# MKM34Z7 register map
Vendor: Freescale Semiconductor, Inc.; Series: Kinetis_M; File version: 1.6
CPU: CM0PLUS r0p0, little endian, no MPU, no FPU, VTOR, 2 interrupt priority bits
Registers are 32-bit, read-write, reset 0x0 unless marked. A register's access mark holds for its fields unless they carry their own. Offsets are from the block's base; [hi:lo] are bit positions; {n}, {i} and the like mark numbered series.

## EWM — External Watchdog Monitor
Base 0x40061000; register names take the prefix EWM_
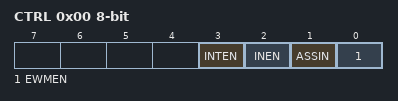
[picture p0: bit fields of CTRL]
0x00 CTRL 8-bit — Control Register
  [3] INTEN — Interrupt Enable.
  [2] INEN — Input Enable.
  [1] ASSIN — EWM_in's Assertion State Select.
  [0] EWMEN — EWM enable.
0x01 SERV 8-bit wo — Service Register
  [7:0] SERVICE — The EWM service mechanism requires the CPU to write two values to the SERV register: a first data byte of 0xB4, followed by a second data byte of 0x2C
0x02 CMPL 8-bit — Compare Low Register
  [7:0] COMPAREL — To prevent runaway code from changing this field, software should write to this field after a CPU reset even if the (default) minimum service time is required
0x03 CMPH 8-bit reset 0xFF — Compare High Register
  [7:0] COMPAREH — To prevent runaway code from changing this field, software should write to this field after a CPU reset even if the (default) maximum service time is required
0x04 CLKCTRL 8-bit — Clock Control Register
  [1:0] CLKSEL — EWM has 4 possible low power clock sources for running EWM counter
0x05 CLKPRESCALER 8-bit — Clock Prescaler Register
  [7:0] CLK_DIV — Selected low power source for running the EWM counter can be prescaled as below

## OSC — Oscillator
Base 0x40066000; register names take the prefix OSC_
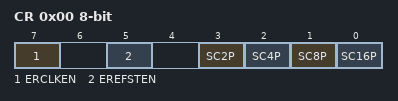
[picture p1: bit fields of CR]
0x00 CR 8-bit — OSC Control Register
  [7] ERCLKEN — External Reference Enable
    0=External reference clock is inactive; 1=External reference clock is enabled
  [5] EREFSTEN — External Reference Stop Enable
    0=External reference clock is disabled in Stop mode; 1=External reference clock stays enabled in Stop mode if ERCLKEN is set before entering Stop mode
  [3] SC2P — Oscillator 2 pF Capacitor Load Configure
    0=Disable the selection; 1=Add 2 pF capacitor to the oscillator load
  [2] SC4P — Oscillator 4 pF Capacitor Load Configure
    0=Disable the selection; 1=Add 4 pF capacitor to the oscillator load
  [1] SC8P — Oscillator 8 pF Capacitor Load Configure
    0=Disable the selection; 1=Add 8 pF capacitor to the oscillator load
  [0] SC16P — Oscillator 16 pF Capacitor Load Configure
    0=Disable the selection; 1=Add 16 pF capacitor to the oscillator load

## VREF — Voltage Reference
Base 0x4006F000; register names take the prefix VREF_
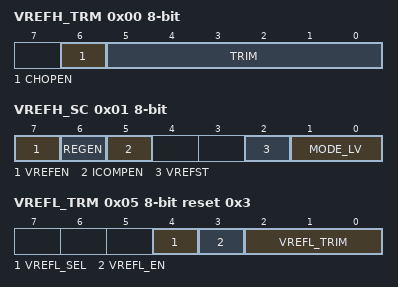
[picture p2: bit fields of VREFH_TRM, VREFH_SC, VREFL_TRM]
0x00 VREFH_TRM 8-bit — VREF Trim Register
  [6] CHOPEN — Chop oscillator enable. When set, internal chopping operation is enabled and the internal analog offset will be minimized.
    0=Chop oscillator is disabled; 1=Chop oscillator is enabled
  [5:0] TRIM — Trim bits
    0=Min; 63=Max
0x01 VREFH_SC 8-bit — VREF Status and Control Register
  [7] VREFEN — Internal Voltage Reference enable
    0=The module is disabled; 1=The module is enabled
  [6] REGEN — Regulator enable
    0=Internal 1.75 V regulator is disabled; 1=Internal 1.75 V regulator is enabled
  [5] ICOMPEN — Second order curvature compensation enable
    0=Disabled; 1=Enabled
  [2] VREFST ro — Internal Voltage Reference stable
    0=The module is disabled or not stable; 1=The module is stable
  [1:0] MODE_LV — Buffer Mode selection
    0=Bandgap on only, for stabilization and startup; 1=High power buffer mode enabled; 2=Low-power buffer mode enabled
0x05 VREFL_TRM 8-bit reset 0x3 — VREFL TRIM Register
  [4] VREFL_SEL — This bit selects between internal and external 1.2 V reference.
    0=Internal reference; 1=External reference
  [3] VREFL_EN — This bit enables the VREFL (0.4 V) reference buffer.
    0=Disable; 1=Enable
  [2:0] VREFL_TRIM — These bits trim the VREFL reference voltage in steps of 10 mV

## CMP0 — High-Speed Comparator (CMP), Voltage Reference (VREF) Digital-to-Analog Converter (DAC), and Analog Mux (ANMUX)
Base 0x40072000; register names take the prefix CMP0_
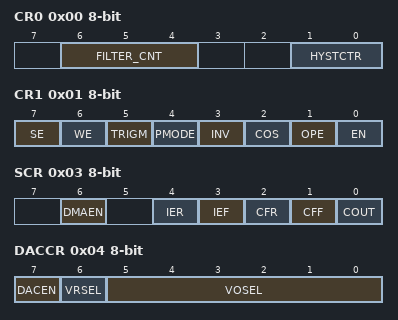
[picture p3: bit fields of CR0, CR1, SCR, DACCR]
0x00 CR0 8-bit — CMP Control Register 0
  [6:4] FILTER_CNT — Filter Sample Count
    0=Filter is disabled. If SE = 1, then COUT is a logic 0. This is not a legal state, and is not recommended. If SE = 0, COUT = COUTA.; 1=One sample must agree. The comparator output is simply sampled.; {v}={v} consecutive samples must agree (v=2..7)
  [1:0] HYSTCTR — Comparator hard block hysteresis control
    {v}=Level {v} (v=0..3)
0x01 CR1 8-bit — CMP Control Register 1
  [7] SE — Sample Enable
    0=Sampling mode is not selected; 1=Sampling mode is selected
  [6] WE — Windowing Enable
    0=Windowing mode is not selected; 1=Windowing mode is selected
  [5] TRIGM — Trigger Mode Enable
    0=Trigger mode is disabled; 1=Trigger mode is enabled
  [4] PMODE — Power Mode Select
    0=Low-Speed (LS) Comparison mode selected. In this mode, CMP has slower output propagation delay and lower current consumption.; 1=High-Speed (HS) Comparison mode selected. In this mode, CMP has faster output propagation delay and higher current consumption.
  [3] INV — Comparator INVERT
    0=Does not invert the comparator output; 1=Inverts the comparator output
  [2] COS — Comparator Output Select
    0=Set the filtered comparator output (CMPO) to equal COUT; 1=Set the unfiltered comparator output (CMPO) to equal COUTA
  [1] OPE — Comparator Output Pin Enable
    0=CMPO is not available on the associated CMPO output pin; 1=CMPO is available on the associated CMPO output pin
  [0] EN — Comparator Module Enable
    0=Analog Comparator is disabled; 1=Analog Comparator is enabled
0x02 FPR 8-bit — CMP Filter Period Register
  [7:0] FILT_PER — Filter Sample Period
0x03 SCR 8-bit — CMP Status and Control Register
  [6] DMAEN — DMA Enable Control
    0=DMA is disabled; 1=DMA is enabled
  [4] IER — Comparator Interrupt Enable Rising
    0=Interrupt is disabled; 1=Interrupt is enabled
  [3] IEF — Comparator Interrupt Enable Falling
    0=Interrupt is disabled; 1=Interrupt is enabled
  [2] CFR — Analog Comparator Flag Rising
    0=Rising-edge on COUT has not been detected; 1=Rising-edge on COUT has occurred
  [1] CFF — Analog Comparator Flag Falling
    0=Falling-edge on COUT has not been detected; 1=Falling-edge on COUT has occurred
  [0] COUT ro — Analog Comparator Output
0x04 DACCR 8-bit — DAC Control Register
  [7] DACEN — DAC Enable
    0=DAC is disabled; 1=DAC is enabled
  [6] VRSEL — Supply Voltage Reference Source Select
    0=Vin1 is selected as resistor ladder network supply reference; 1=Vin2 is selected as resistor ladder network supply reference
  [5:0] VOSEL — DAC Output Voltage Select
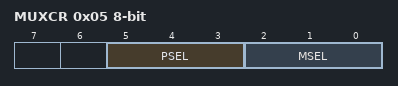
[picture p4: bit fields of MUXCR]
0x05 MUXCR 8-bit — MUX Control Register
  [5:3] PSEL — Plus Input Mux Control
    {v}=IN{v} (v=0..7)
  [2:0] MSEL — Minus Input Mux Control
    {v}=IN{v} (v=0..7)

## CMP1 — High-Speed Comparator (CMP), Voltage Reference (VREF) Digital-to-Analog Converter (DAC), and Analog Mux (ANMUX)
Base 0x40072008; register names take the prefix CMP1_
Registers as CMP0.

## CMP2 — High-Speed Comparator (CMP), Voltage Reference (VREF) Digital-to-Analog Converter (DAC), and Analog Mux (ANMUX)
Base 0x40072010; register names take the prefix CMP2_
Registers as CMP0.
